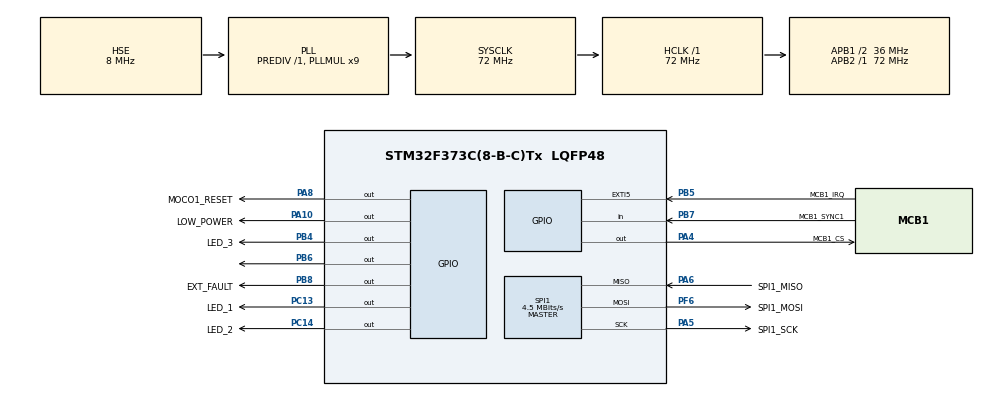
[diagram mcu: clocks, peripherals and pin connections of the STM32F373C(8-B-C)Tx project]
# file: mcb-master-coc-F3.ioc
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Mcu.Family=STM32F3
Mcu.Name=STM32F373C(8-B-C)Tx
Mcu.Package=LQFP48
NVIC.EXTI9_5_IRQn=true\:2\:0\:true\:false\:true\:true\:true
NVIC.PVD_IRQn=true\:3\:0\:true\:false\:true\:true\:true
NVIC.PriorityGroup=NVIC_PRIORITYGROUP_4
NVIC.TIM2_IRQn=true\:3\:0\:true\:false\:true\:true\:true
PA10.GPIO_Label=LOW_POWER
PA10.PinState=GPIO_PIN_SET
PA10.Signal=GPIO_Output
PA13.Mode=Serial_Wire
PA13.Signal=SYS_JTMS-SWDIO
PA14.Mode=Serial_Wire
PA14.Signal=SYS_JTCK-SWCLK
PA4.GPIO_Label=MCB1_CS
PA4.PinState=GPIO_PIN_SET
PA4.Signal=GPIO_Output
PA5.GPIO_Label=SPI1_SCK
PA5.GPIO_PuPd=GPIO_PULLUP
PA5.Mode=Full_Duplex_Master
PA5.Signal=SPI1_SCK
PA6.GPIO_Label=SPI1_MISO
PA6.Mode=Full_Duplex_Master
PA6.Signal=SPI1_MISO
PA8.GPIO_Label=MOCO1_RESET
PA8.Signal=GPIO_Output
PB4.GPIO_Label=LED_3
PB4.Signal=GPIO_Output
PB5.GPIO_Label=MCB1_IRQ
PB5.Signal=GPXTI5
PB6.Signal=GPIO_Output
PB7.GPIO_Label=MCB1_SYNC1
PB7.Signal=GPIO_Input
PB8.GPIO_Label=EXT_FAULT
PB8.PinState=GPIO_PIN_SET
PB8.Signal=GPIO_Output
PC13.GPIO_Label=LED_1
PC13.Signal=GPIO_Output
PC14-OSC32_IN.GPIO_Label=LED_2
PC14-OSC32_IN.Signal=GPIO_Output
PF0-OSC_IN.Mode=HSE-External-Oscillator
PF0-OSC_IN.Signal=RCC_OSC_IN
PF1-OSC_OUT.Mode=HSE-External-Oscillator
PF1-OSC_OUT.Signal=RCC_OSC_OUT
PF6.GPIO_Label=SPI1_MOSI
PF6.Mode=Full_Duplex_Master
PF6.Signal=SPI1_MOSI
ProjectManager.HeapSize=0x200
ProjectManager.StackSize=0x400
ProjectManager.TargetToolchain=STM32CubeIDE
RCC.AHBFreq_Value=72000000
RCC.APB1CLKDivider=RCC_HCLK_DIV2
RCC.APB1Freq_Value=36000000
RCC.APB1TimFreq_Value=72000000
RCC.APB2Freq_Value=72000000
RCC.APB2TimFreq_Value=72000000
RCC.CortexFreq_Value=72000000
RCC.HCLKFreq_Value=72000000
RCC.HSE_VALUE=8000000
RCC.HSI_VALUE=8000000
RCC.LSE_VALUE=32768
RCC.PLLMUL=RCC_PLL_MUL9
RCC.PLLSourceVirtual=RCC_PLLSOURCE_HSE
RCC.SYSCLKFreq_VALUE=72000000
RCC.SYSCLKSource=RCC_SYSCLKSOURCE_PLLCLK
RCC.USBFreq_Value=72000000
SPI1.BaudRatePrescaler=SPI_BAUDRATEPRESCALER_16
SPI1.CLKPolarity=SPI_POLARITY_HIGH
SPI1.CRCCalculation=SPI_CRCCALCULATION_ENABLE
SPI1.CRCLength=SPI_CRC_LENGTH_16BIT
SPI1.CRCPolynomial=X12+X5+X0
SPI1.CalculateBaudRate=4.5 MBits/s
SPI1.DataSize=SPI_DATASIZE_16BIT
SPI1.Direction=SPI_DIRECTION_2LINES
SPI1.Mode=SPI_MODE_MASTER
SPI1.NSSPMode=SPI_NSS_PULSE_ENABLE
SPI1.VirtualType=VM_MASTER
TIM2.Period=144000
VP_TIM2_VS_ClockSourceINT.Mode=Internal
board=custom

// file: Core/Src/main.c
/* USER CODE BEGIN Header */
/**
  ******************************************************************************
  * @file           : main.c
  * @brief          : Main program body
  ******************************************************************************
  * @attention
  *
  * <h2><center>&copy; Copyright (c) 2019 STMicroelectronics.
  * All rights reserved.</center></h2>
  *
  * This software component is licensed by ST under BSD 3-Clause license,
  * the "License"; You may not use this file except in compliance with the
  * License. You may obtain a copy of the License at:
  *                        opensource.org/licenses/BSD-3-Clause
  *
  ******************************************************************************
  */
/* USER CODE END Header */
#include "main.h"
#include "spi.h"
#include "tim.h"
#include "gpio.h"

/* USER CODE BEGIN Includes */
#include "application.h"
#include <string.h>

/* USER CODE END Includes */

void SystemClock_Config(void);

int main(void)
{

  /* MCU Configuration--------------------------------------------------------*/

  /* Reset of all peripherals, Initializes the Flash interface and the Systick. */
  HAL_Init();

  /* Configure the system clock */
  SystemClock_Config();

  /* Initialize all configured peripherals */
  MX_GPIO_Init();
  MX_SPI1_Init();
  MX_TIM2_Init();
  /* USER CODE BEGIN 2 */

  AppInit();

  /* USER CODE END 2 */

  /* Infinite loop */
  /* USER CODE BEGIN WHILE */
  AppStart();

  /** Start the timer used for cyclic communication */
  HAL_TIM_Base_Start_IT(&htim2);

  while (1)
  {
    /* USER CODE END WHILE */

    /* USER CODE BEGIN 3 */
    if (AppLoop() != (int32_t)0L)
    {
        break;
    }

    HAL_Delay(1);
  }
  /* USER CODE END 3 */
}

void SystemClock_Config(void)
{
  RCC_OscInitTypeDef RCC_OscInitStruct = {0};
  RCC_ClkInitTypeDef RCC_ClkInitStruct = {0};

  /** Initializes the RCC Oscillators according to the specified parameters
  * in the RCC_OscInitTypeDef structure.
  */
  RCC_OscInitStruct.OscillatorType = RCC_OSCILLATORTYPE_HSE;
  RCC_OscInitStruct.HSEState = RCC_HSE_ON;
  RCC_OscInitStruct.HSEPredivValue = RCC_HSE_PREDIV_DIV1;
  RCC_OscInitStruct.HSIState = RCC_HSI_ON;
  RCC_OscInitStruct.PLL.PLLState = RCC_PLL_ON;
  RCC_OscInitStruct.PLL.PLLSource = RCC_PLLSOURCE_HSE;
  RCC_OscInitStruct.PLL.PLLMUL = RCC_PLL_MUL9;
  if (HAL_RCC_OscConfig(&RCC_OscInitStruct) != HAL_OK)
  {
    Error_Handler();
  }
  /** Initializes the CPU, AHB and APB buses clocks
  */
  RCC_ClkInitStruct.ClockType = RCC_CLOCKTYPE_HCLK|RCC_CLOCKTYPE_SYSCLK
                              |RCC_CLOCKTYPE_PCLK1|RCC_CLOCKTYPE_PCLK2;
  RCC_ClkInitStruct.SYSCLKSource = RCC_SYSCLKSOURCE_PLLCLK;
  RCC_ClkInitStruct.AHBCLKDivider = RCC_SYSCLK_DIV1;
  RCC_ClkInitStruct.APB1CLKDivider = RCC_HCLK_DIV2;
  RCC_ClkInitStruct.APB2CLKDivider = RCC_HCLK_DIV1;

  if (HAL_RCC_ClockConfig(&RCC_ClkInitStruct, FLASH_LATENCY_2) != HAL_OK)
  {
    Error_Handler();
  }
}

/* USER CODE BEGIN 4 */
void HAL_TIM_PeriodElapsedCallback(TIM_HandleTypeDef *htim)
{
    if (htim->Instance == TIM2)
    {
        AppCyclicProcess();
    }
}

/* USER CODE END 4 */

void Error_Handler(void)
{
}

/************************ (C) COPYRIGHT STMicroelectronics *****END OF FILE****/
